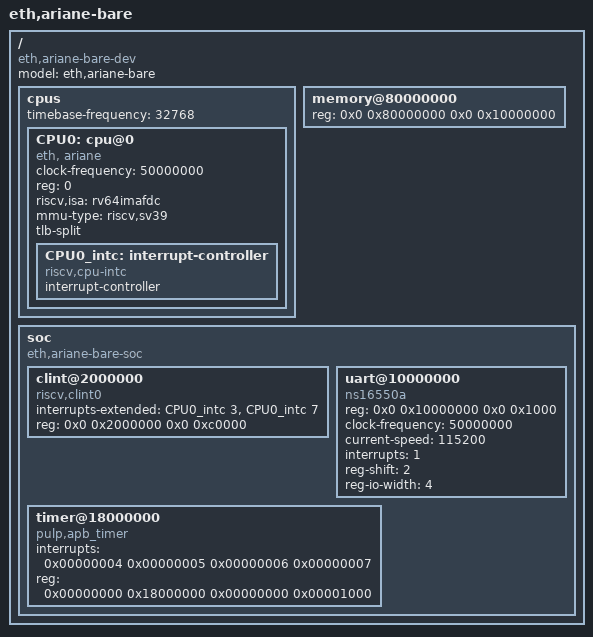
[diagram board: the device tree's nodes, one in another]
/dts-v1/;

/ {
  #address-cells = <2>;
  #size-cells = <2>;
  compatible = "eth,ariane-bare-dev";
  model = "eth,ariane-bare";
  cpus {
    #address-cells = <1>;
    #size-cells = <0>;
    timebase-frequency = <32768>; // 32.768 kHz
    CPU0: cpu@0 {
      clock-frequency = <50000000>; // 50 MHz
      device_type = "cpu";
      reg = <0>;
      status = "okay";
      compatible = "eth, ariane", "riscv";
      riscv,isa = "rv64imafdc";
      mmu-type = "riscv,sv39";
      tlb-split;
      // HLIC - hart local interrupt controller
      CPU0_intc: interrupt-controller {
        #interrupt-cells = <1>;
        interrupt-controller;
        compatible = "riscv,cpu-intc";
      };
    };
  };
  memory@80000000 {
    device_type = "memory";
    reg = <0x0 0x80000000 0x0 0x10000000>;
  };
  soc {
    #address-cells = <2>;
    #size-cells = <2>;
    compatible = "eth,ariane-bare-soc", "simple-bus";
    ranges;
    clint@2000000 {
      compatible = "riscv,clint0";
      interrupts-extended = <&CPU0_intc 3 &CPU0_intc 7>;
      reg = <0x0 0x2000000 0x0 0xc0000>;
      reg-names = "control";
    };
    // PLIC needs to be disabeld for tandem verification
    // PLIC0: interrupt-controller@c000000 {
    //   #address-cells = <0>;
    //   #interrupt-cells = <1>;
    //   compatible = "sifive,plic-1.0.0", "riscv,plic0";
    //   interrupt-controller;
    //   interrupts-extended = <&CPU0_intc 11 &CPU0_intc 9>;
    //   reg = <0x0 0xc000000 0x0 0x4000000>;
    //   riscv,max-priority = <7>;
    //   riscv,ndev = <2>;
    // };
    // Specifying the interrupt controller in the devicetree is not necessary.
    // Furthermore, the IRQ 65535 will cause a `hwirq 0xffff is too large` during
    // Linux boot (occured with mainline linux 5.14.0).
    // debug-controller@0 {
    //   compatible = "riscv,debug-013";
    //   interrupts-extended = <&CPU0_intc 65535>;
    //   reg = <0x0 0x0 0x0 0x1000>;
    //   reg-names = "control";
    // };
    uart@10000000 {
      compatible = "ns16550a";
      reg = <0x0 0x10000000 0x0 0x1000>;
      clock-frequency = <50000000>;
      current-speed = <115200>;
      // interrupt-parent = <&PLIC0>;
      interrupts = <1>;
      reg-shift = <2>; // regs are spaced on 32 bit boundary
      reg-io-width = <4>; // only 32-bit access are supported
    };
    timer@18000000 {
      compatible = "pulp,apb_timer";
      interrupts = <0x00000004 0x00000005 0x00000006 0x00000007>;
      reg = <0x00000000 0x18000000 0x00000000 0x00001000>;
      // interrupt-parent = <&PLIC0>;
      reg-names = "control";
    };
  };
};
